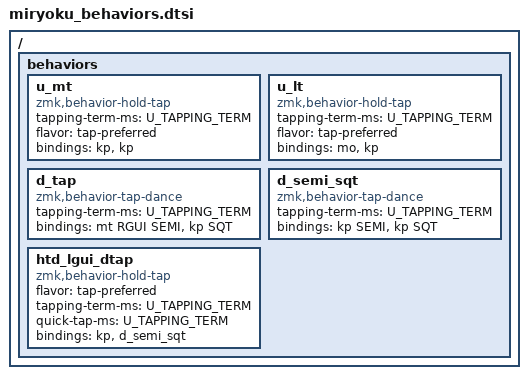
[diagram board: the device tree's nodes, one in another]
// Copyright 2022 Manna Harbour
// https://github.com/manna-harbour/miryoku

/ {
  behaviors {
    u_mt: u_mt {
      compatible = "zmk,behavior-hold-tap";
      #binding-cells = <2>;
      tapping-term-ms = <U_TAPPING_TERM>;
      flavor = "tap-preferred";
      bindings = <&kp>, <&kp>;
    };
    u_lt: u_lt {
      compatible = "zmk,behavior-hold-tap";
      #binding-cells = <2>;
      tapping-term-ms = <U_TAPPING_TERM>;
      flavor = "tap-preferred";
      bindings = <&mo>, <&kp>;
    };
    d_tap: d_tap {
      compatible = "zmk,behavior-tap-dance";
      #binding-cells = <0>;
      tapping-term-ms = <U_TAPPING_TERM>;
      bindings = <&mt RGUI SEMI>, <&kp SQT>;
    };
    d_semi_sqt: d_semi_sqt {
        compatible = "zmk,behavior-tap-dance";
        #binding-cells = <0>;
        tapping-term-ms = <U_TAPPING_TERM>;
        bindings = <&kp SEMI>, <&kp SQT>;
    };
    htd_lgui_dtap: htd_lgui_dtap {
        compatible = "zmk,behavior-hold-tap";
        #binding-cells = <2>;
        flavor = "tap-preferred";
        tapping-term-ms = <U_TAPPING_TERM>;
        quick-tap-ms = <U_TAPPING_TERM>;
        bindings = <&kp>, <&d_semi_sqt>;
    };
  };
};
